# STM32WLE5xx register map
File version: 1.0
Registers are 32-bit, read-write, reset 0x0 unless marked. A register's access mark holds for its fields unless they carry their own. Offsets are from the block's base; [hi:lo] are bit positions; {n}, {i} and the like mark numbered series.

## RNG
Base 0x58001000
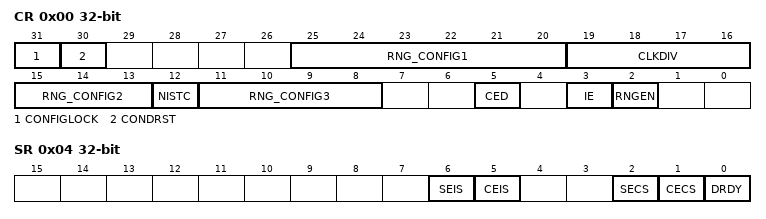
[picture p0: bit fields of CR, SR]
0x00 CR — RNG control register
  [31] CONFIGLOCK
  [30] CONDRST
  [25:20] RNG_CONFIG1
  [19:16] CLKDIV
    0=BY_1 (No clock division); 1=BY_2 (2 RNG clock cycles per internal RNG clock); 2=BY_4 (4 RNG clock cycles per internal RNG clock); 3=BY_8 (8 RNG clock cycles per internal RNG clock); 4=BY_16 (16 RNG clock cycles per internal RNG clock); 5=BY_32 (32 RNG clock cycles per internal RNG clock); 6=BY_64 (64 RNG clock cycles per internal RNG clock); 7=BY_128 (128 RNG clock cycles per internal RNG clock); 8=BY_256 (256 RNG clock cycles per internal RNG clock); 9=BY_512 (512 RNG clock cycles per internal RNG clock); 10=BY_1024 (1024 RNG clock cycles per internal RNG clock); 11=BY_2048 (2048 RNG clock cycles per internal RNG clock); 12=BY_4096 (4096 RNG clock cycles per internal RNG clock); 13=BY_8192 (8192 RNG clock cycles per internal RNG clock); 14=BY_16384 (16384 RNG clock cycles per internal RNG clock); 15=BY_32768 (32768 RNG clock cycles per internal RNG clock)
  [15:13] RNG_CONFIG2
  [12] NISTC
  [11:8] RNG_CONFIG3
  [5] CED
  [3] IE
  [2] RNGEN
0x04 SR — RNG status register
  [6] SEIS, [5] CEIS, [2] SECS, [1] CECS, [0] DRDY
0x08 DR — RNG data register
  [31:0] RNDATA
0x10 HTCR — RNG health test control register
  [31:0] HTCFG

## HSEM — HW Semaphore HSEM
Base 0x58001400
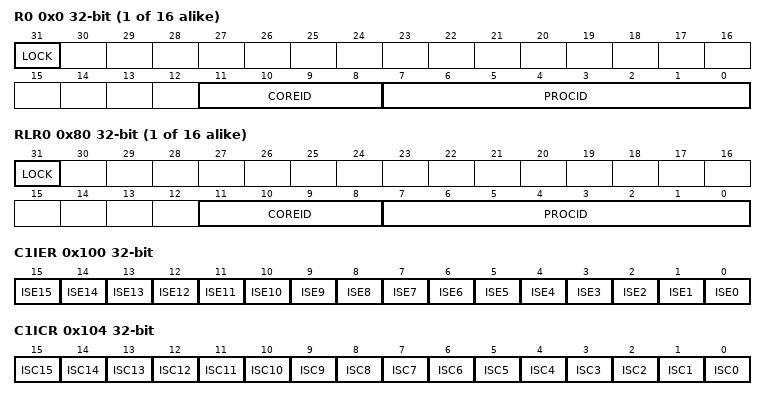
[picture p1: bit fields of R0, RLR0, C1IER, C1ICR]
{0x0+4i} R{i} (i=0..15) — HSEM 2-step write lock and read back registers
  [31] LOCK — Lock indication
  [11:8] COREID — Semaphore CoreID
    0=NONE; 4=CPU1
  [7:0] PROCID — Semaphore ProcessID
{0x80+4i} RLR{i} (i=0..15) — HSEM 1-step read lock registers
  [31] LOCK — Lock indication
  [11:8] COREID — Semaphore CoreID
  [7:0] PROCID — Semaphore ProcessID
0x100 C1IER — HSEM CPU1 interrupt enable register
  [n] ISE{n} (n=0..15) — semaphore {n} CPU1 interrupt enable bit
0x104 C1ICR — HSEM CPU1 interrupt clear register
  [n] ISC{n} (n=0..15) — semaphore {n} CPU1 interrupt clear bit
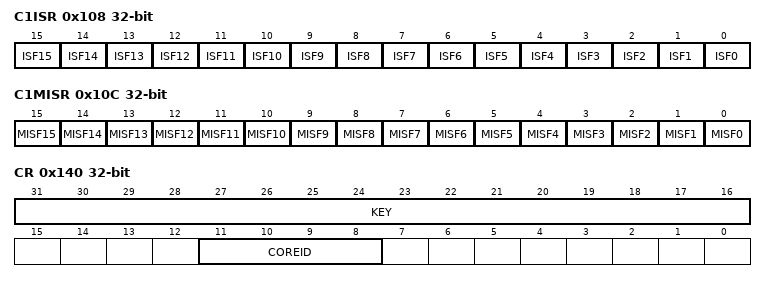
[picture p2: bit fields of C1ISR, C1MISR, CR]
0x108 C1ISR — HSEM CPU1 interrupt status register
  [n] ISF{n} (n=0..15) — semaphore {n} CPU1 interrupt status bit
0x10C C1MISR — HSEM CPU1 masked interrupt status register
  [n] MISF{n} (n=0..15) — semaphore {n} CPU1 interrupt masked status bit
0x140 CR — HSEM Semaphore clear register
  [31:16] KEY — semaphores clear key
  [11:8] COREID — CoreID of semaphores to be cleared
0x144 KEYR — HSEM Semaphore clear key register
  [31:16] KEY — semaphores clear key

## AES — AES hardware accelerator
Base 0x58001800
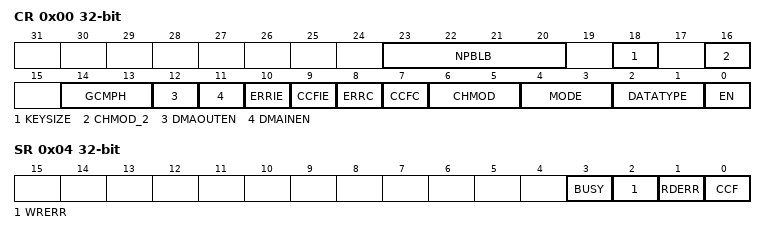
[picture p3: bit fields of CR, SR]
0x00 CR — AES control register
  [23:20] NPBLB — Number of padding bytes in last payload block
  [18] KEYSIZE — Key size selection
  [16] CHMOD_2 — AES Chaining Mode
  [14:13] GCMPH — GCM Phase
  [12] DMAOUTEN — Enable data output phase DMA management
  [11] DMAINEN — Enable data input phase DMA management
  [10] ERRIE — Error Interrupt Enable
  [9] CCFIE — Computation Complete Flag Interrupt Enable
  [8] ERRC — Error Clear
  [7] CCFC — Computation Complete Flag Clear
  [6:5] CHMOD — AES Chaining Mode
  [4:3] MODE — AES Mode Of Operation
  [2:1] DATATYPE — Data type selection
  [0] EN — AES Enable
0x04 SR — AES status register
  [3] BUSY — Busy Flag
  [2] WRERR — Write Error Flag
  [1] RDERR — Read Error Flag
  [0] CCF — Computation Complete Flag
0x08 DINR — AES data input register
  [31:0] DINR — AES Data Input Register
0x0C DOUTR — AES data output register
  [31:0] DOUTR — AES Data Output Register
{0x10+4i} KEYR{i} (i=0..3) — AES key register {i}
  [31:0] KEYR{i} — AES Key Register {i}
{0x20+4i} IVR{i} (i=0..3) — AES initialization vector register {i}
  [31:0] IVR{i} — AES Initialization Vector Register {i}
{0x20+4i} KEYR{i} (i=4..7) — AES key register {i}
  [31:0] KEYR{i} — AES Key Register {i}
{0x40+4i} SUSP{i}R (i=0..7) — AES Suspend register {i}
  [31:0] SUSP{i}R — AES Suspend registers {i}
